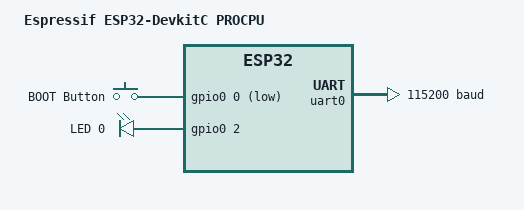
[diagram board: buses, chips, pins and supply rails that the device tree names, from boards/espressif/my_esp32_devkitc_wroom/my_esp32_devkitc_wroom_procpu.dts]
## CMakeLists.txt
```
# Copyright (c) 2021 Nordic Semiconductor ASA
# SPDX-License-Identifier: Apache-2.0
#
# This CMake file is picked by the Zephyr build system because it is defined
# as the module CMake entry point (see zephyr/module.yml).
cmake_minimum_required(VERSION 3.22)

# Set board
set(BOARD my_esp32_devkitc_wroom/esp32/procpu)
set(BOARD_ROOT ${CMAKE_CURRENT_SOURCE_DIR})

# Add zephyr base path
find_package(Zephyr REQUIRED HINTS $ENV{ZEPHYR_BASE})

# Add project name
project(wicked_bubble_fw)

# How to add message on build
#message(STATUS "ZEPHYR_BASE = ${ZEPHYR_BASE}")

# Add include path
zephyr_include_directories(include)

target_sources(app PRIVATE
                src/main.c
                src/thread_msg/message_hmi_main.c
                src/thread_msg/message_iot_main.c
                src/thread_msg/message_main_bubble.c
                src/hmi/uart_cmd.c
                src/io_bubble/bubble_control.c
                src/iot/iot_thread.c
                src/iot/iot_mqtt.c
)

target_include_directories(app PRIVATE  src
                                        src/hmi
                                        src/io_bubble
                                        src/thread_msg
                                        src/iot
)
```

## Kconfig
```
# Copyright (c) 2021 Nordic Semiconductor ASA
# SPDX-License-Identifier: Apache-2.0
#
# This Kconfig file is picked by the Zephyr build system because it is defined
# as the module Kconfig entry point (see zephyr/module.yml). You can browse
# module options by going to Zephyr -> Modules in Kconfig.

source "Kconfig.zephyr"
```

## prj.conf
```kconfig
# Copyright (c) 2021 Nordic Semiconductor ASA
# SPDX-License-Identifier: Apache-2.0
#
# This file contains selected Kconfig options for the application.
CONFIG_GPIO=y
#CONFIG_PWM=y

CONFIG_SERIAL=y
CONFIG_UART_INTERRUPT_DRIVEN=y
CONFIG_RING_BUFFER=y

#CONFIG_SHELL=n
# Enable Shell over UART (for command input)
#CONFIG_SHELL_BACKEND_SERIAL=y

# Optional: Increase shell stack size
# CONFIG_SHELL_STACK_SIZE=4096

# Enable logging over UART (for debug prints)
# CONFIG_LOG=y
# CONFIG_LOG_BACKEND_UART=y
```

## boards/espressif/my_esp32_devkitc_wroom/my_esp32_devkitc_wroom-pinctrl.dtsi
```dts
/*
 * Copyright (c) 2022 Espressif Systems (Shanghai) Co., Ltd.
 *
 * SPDX-License-Identifier: Apache-2.0
 */

#include <zephyr/dt-bindings/pinctrl/esp-pinctrl-common.h>
#include <dt-bindings/pinctrl/esp32-pinctrl.h>
#include <zephyr/dt-bindings/pinctrl/esp32-gpio-sigmap.h>

&pinctrl {
	uart0_default: uart0_default {
		group1 {
			pinmux = <UART0_TX_GPIO1>;
			output-high;
		};
		group2 {
			pinmux = <UART0_RX_GPIO3>;
			bias-pull-up;
		};
	};

	mcpwm0_default: mcpwm0_default {
		group1 {
			pinmux = <MCPWM0_OUT0A_GPIO2>,
					<MCPWM0_OUT0A_GPIO4>;
			output-enable;
		};
	};
};
```

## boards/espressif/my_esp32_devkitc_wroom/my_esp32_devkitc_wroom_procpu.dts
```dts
/*
 * Copyright (c) 2023 Espressif Systems (Shanghai) Co., Ltd.
 *
 * SPDX-License-Identifier: Apache-2.0
 */
/dts-v1/;

#include <espressif/esp32/esp32_wroom_32ue_n4.dtsi>
#include "my_esp32_devkitc_wroom-pinctrl.dtsi"
#include <zephyr/dt-bindings/input/input-event-codes.h>
#include <espressif/partitions_0x1000_amp.dtsi>

/ {
	model = "Espressif ESP32-DevkitC PROCPU";
	compatible = "espressif,esp32";

	aliases {
		uart-0 = &uart0;
		i2c-0 = &i2c0;
		sw0 = &button0;
		watchdog0 = &wdt0;
		led0 = &led0;
	};

	buttons {
		compatible = "gpio-keys";
		button0: button_0 {
			gpios = <&gpio0 0 (GPIO_PULL_UP | GPIO_ACTIVE_LOW)>;
			label = "BOOT Button";
			zephyr,code = <INPUT_KEY_0>;
		};
	};

	leds {
		compatible = "gpio-leds";
		led0: led_0 {
			gpios = <&gpio0 2 GPIO_ACTIVE_HIGH>;
			label = "LED 0";
		};
	};

	wifi_sta: wifi_sta {
		compatible = "espressif,esp32-wifi";
		status = "okay";
	};

	chosen {
		zephyr,sram = &sram1;
		zephyr,console = &uart0;
		zephyr,shell-uart = &uart0;
		zephyr,flash = &flash0;
		zephyr,code-partition = &slot0_partition;
	};
};

&uart0 {
	status = "okay";
	current-speed = <115200>;
	pinctrl-0 = <&uart0_default>;
	pinctrl-names = "default";
};

&gpio0 {
	status = "okay";
};

&gpio1 {
	status = "okay";
};
```

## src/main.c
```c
/*
 * Copyright (c) 2021 Nordic Semiconductor ASA
 * SPDX-License-Identifier: Apache-2.0
 */

#include <zephyr/kernel.h>
#include <app_version.h>
#include "uart_cmd.h"
#include "bubble_control.h"
#include "message_hmi_main.h"
#include "message_main_bubble.h"

void handle_hmi_msg(void)
{
    static struct hmi_msg_t hmi_msg = {};
    if (recv_message_hmi_to_main(&hmi_msg) != 0) {
        return;
    }

    switch (hmi_msg.module) {
        case MOD_MAIN:
            //printk("HMI Command to Main Thread\n");
            break;
        case MOD_BUBBLE:
            //printk("HMI Command to Bubble Thread\n");
            struct main_to_bubble_msg_t main_to_bubble = {0};
            if (hmi_msg.type == HMI_CMD_BUBBLE_ON) {
                main_to_bubble.type = MAIN_CMD_BUBBLE_ON;
            } else if (hmi_msg.type == HMI_CMD_BUBBLE_OFF) {
                main_to_bubble.type = MAIN_CMD_BUBBLE_OFF;
            } else {
                return;
            }
            send_message_main_to_bubble(&main_to_bubble);
            //TODO: Handle return from message sent
            break;
        default:
            printk("Command not recognized from HMI: %02X", hmi_msg.type);
            break;
    }
}

int main(void)
{
    printk("Zephyr Example Application %s\n", APP_VERSION_STRING);

    bubble_thread_start();
    uart_thread_start();

    while (1) {
        // Handle communication with all threads
        handle_hmi_msg();
        // Read data from HMI Thread
        // Read data from Wifi/MQTT
        // Write data to Servo Thread
        // Read data from servo thread
        k_msleep(50);  // Delay to avoid CPU usage
    }

    return 0;
}
```

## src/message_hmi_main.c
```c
/*
 * Copyright (c) 2021 Nordic Semiconductor ASA
 * SPDX-License-Identifier: Apache-2.0
 */

#include <zephyr/kernel.h>
#include "message_hmi_main.h"

K_MSGQ_DEFINE(hmi_msgq, sizeof(struct hmi_msg_t), 5, 4);
K_MSGQ_DEFINE(main_to_bubble_msgq, sizeof(struct main_to_bubble_msg_t), 5, 4);

// HMI -> Main Message
int send_message_hmi_to_main(struct hmi_msg_t *hmi_data) {
    return k_msgq_put(&hmi_msgq, hmi_data, K_NO_WAIT);
}
int recv_message_hmi_to_main(struct hmi_msg_t *hmi_data) {
    return k_msgq_get(&hmi_msgq, hmi_data, K_NO_WAIT);
}

// Main -> Bubble IO Message
int send_message_main_to_bubble(struct main_to_bubble_msg_t *msg) {
    return k_msgq_put(&main_to_bubble_msgq, msg, K_NO_WAIT);
}
int recv_message_main_to_bubble(struct main_to_bubble_msg_t *msg) {
    return k_msgq_get(&main_to_bubble_msgq, msg, K_NO_WAIT);
}
```

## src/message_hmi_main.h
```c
#ifndef MSG_HMI_MAIN_H_
#define MSG_HMI_MAIN_H_

#include <stdint.h>
#include <zephyr/kernel.h>

enum hmi_cmd_type {
    HMI_CMD_BUBBLE_ON,
    HMI_CMD_BUBBLE_OFF,
};

enum hmi_module_type {
    MOD_MAIN,
    MOD_BUBBLE
};

// HMI -> Main Message
struct hmi_msg_t {
    enum hmi_module_type module;
    enum hmi_cmd_type type;
};

int send_message_hmi_to_main(struct hmi_msg_t *hmi_data);
int recv_message_hmi_to_main(struct hmi_msg_t *hmi_data);

// TODO: Move this below to another file and create an message folder containing messages data
enum main_to_bubble_cmd_type {
    MAIN_CMD_BUBBLE_ON,
    MAIN_CMD_BUBBLE_OFF,
};

// Main -> Servo Message
struct main_to_bubble_msg_t {
    enum main_to_bubble_cmd_type type;
};

int send_message_main_to_bubble(struct main_to_bubble_msg_t *msg);
int recv_message_main_to_bubble(struct main_to_bubble_msg_t *msg);

#endif
```
